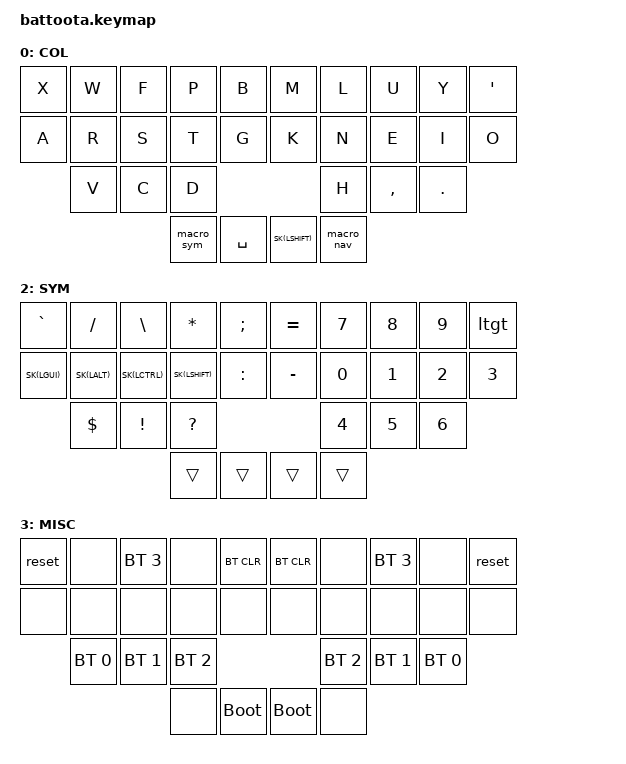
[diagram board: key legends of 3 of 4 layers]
/*
 * Copyright (c) 2020 The ZMK Contributors
 *
 * SPDX-License-Identifier: MIT
 */

#include <behaviors.dtsi>
#include <dt-bindings/zmk/keys.h>
#include <dt-bindings/zmk/bt.h>
#include <dt-bindings/zmk/outputs.h>

#define COL 0
#define NAV 1
#define SYM 2
#define MISC 4

#define SK(KEY) &nk KEY KEY
// Keep sticky keys active for a long time so they effectively do not time out
#define STICKY_KEY_TIMEOUT 60000

&sk {
  release-after-ms = <STICKY_KEY_TIMEOUT>;
};

&caps_word {
  continue-list = <UNDERSCORE MINUS BACKSPACE>;
};

/ { 

     ZMK_MACRO(macro_nav,
        wait-ms = <0>;
        tap-ms = <0>;
        bindings
        = <&macro_tap &kp K_CANCEL>
        , <&macro_press &mo NAV>
        , <&macro_pause_for_release>
        , <&macro_release &mo NAV>;)

     ZMK_MACRO(macro_sym,
        wait-ms = <0>;
        tap-ms = <0>;
        bindings
        = <&macro_tap &kp K_CANCEL>
        , <&macro_press &mo SYM>
        , <&macro_pause_for_release>
        , <&macro_release &mo SYM>;)

     ZMK_MACRO(macro_power,
        wait-ms = <30>;
        tap-ms = <40>;
        bindings
        = <&macro_tap_time 1000> 
        , <&kp C_POWER>;)

     ZMK_MACRO(macro_sleep,
        wait-ms = <30>;
        tap-ms = <40>;
        bindings
        = <&macro_tap_time 1000> 
        , <&kp C_SLEEP>;)

    combos {
        compatible = "zmk,combos"; 
        #define COMBO(NAME, BINDINGS, KEYPOS, LAYERS) \
        combo_##NAME { \
            bindings = <BINDINGS>; \
            timeout-ms = <40>; \
            key-positions = <KEYPOS>; \
            layers = <LAYERS>; \
        };

        /* Missing Alphas */
        COMBO(Z, &kp Z, 21 22, COL) // Z 
        COMBO(Q, &kp Q, 20 21, COL) // Q
        COMBO(Q2, &kp Q, 2 3, COL) // Q for vim wq
        COMBO(J, &kp J, 1 2, COL) // J 
        COMBO(slash, &kp SLASH, 24 25, COL) // slash
        COMBO(dot, &kp DOT, 16 17, SYM) // .
        COMBO(comma, &kp COMMA, 17 18, SYM) // ,

        /* Brackets */
        COMBO(left_bracket, &kp LBKT, 1 11, COL)
        COMBO(right_bracket, &kp RBKT, 8 18, COL)
        COMBO(left_parenthesis, &kp LPAR, 2 12, COL)
        COMBO(right_parenthesis, &kp RPAR, 7 17, COL)
        COMBO(left_brace, &kp LBRC, 3 13, COL)
        COMBO(right_brace, &kp RBRC, 6 16, COL)

        /* Text processing */
        COMBO(undo, &kp LG(Z), 10 20, COL)
        COMBO(redo, &kp LG(LS(Z)), 10 21, COL)
        COMBO(select_all, &kp LG(A), 10 22, COL)
        COMBO(cut, &kp LG(X), 11 20 , COL)
        COMBO(copy, &kp LG(C), 12 21, COL)
        COMBO(paste, &kp LG(V), 20 21 22, COL)
        COMBO(caps_word, &caps_word, 27 28, COL)

        /* one hand */
        COMBO(nav1h, &macro_nav, 26 27, COL)
        COMBO(sym1h, &macro_sym, 28 29, COL)

        /* misc */
        COMBO(alfred, &kp LG(SPACE), 22 23, COL)
        COMBO(clpbrd, &kp LG(LC(LA(LS(Z)))), 14 15, COL)
        COMBO(esc, &kp ESC, 22 26, COL)
        COMBO(enter, &kp ENTER, 13 22, COL)
        COMBO(backspace, &kp BACKSPACE, 4 14, COL)
        COMBO(key_repeat, &key_repeat, 16 23, COL)
        COMBO(delete_word, &kp LA(BACKSPACE), 5 15, COL)

        #define GCOMBO(NAME, BINDINGS, KEYPOS) \
        combo_##NAME { \
            bindings = <BINDINGS>; \
            key-positions = <KEYPOS>; \
        };
        /* layers */
        GCOMBO(switch_to_mac, &to COL, 12 13 26)
        GCOMBO(misc_layertL, &to MISC, 11 12 13 14)
        GCOMBO(misc_layerR, &to MISC, 15 16 17 18)

    };
  
    // Sticky key on tap, normal key on hold
    // Useful for modifier-clicking without the modifier remaining active
     nk: not_so_sticky_key {
       compatible = "zmk,behavior-hold-tap";
       label = "NOT_SO_STICKY_KEY";
       #binding-cells = <2>;
       tapping_term_ms = <200>;
       flavor = "tap-preferred";
       bindings = <&kp>, <&sk>;
     };

     ltgt: smaller_bigger {
            compatible = "zmk,behavior-mod-morph";
            label = "SMALLER_BIGGER";
            #binding-cells = <0>;
            bindings = <&kp LT>, <&kp GT>;
            mods = <(MOD_LSFT)>;
        };
 
        keymap {
                compatible = "zmk,keymap";

        colemak {
            label = "COL";
            bindings = <
// ╭─────────────┬─────────────┬─────────────┬─────────────┬─────────────╮   ╭─────────────┬─────────────┬─────────────┬─────────────┬─────────────╮
     &kp X         &kp W         &kp F         &kp P         &kp B             &kp M         &kp L         &kp U         &kp Y         &kp SQT
// ├─────────────┼─────────────┼─────────────┼─────────────┼─────────────┤   ├─────────────┼─────────────┼─────────────┼─────────────┼─────────────┤
     &kp A         &kp R         &kp S         &kp T         &kp G             &kp K         &kp N         &kp E         &kp I         &kp O
// ├─────────────┼─────────────┼─────────────┼─────────────┼─────────────┤   ├─────────────┼─────────────┼─────────────┼─────────────┼─────────────┤
                   &kp V         &kp C         &kp D                                         &kp H         &kp COMMA     &kp DOT
//               ╰─────────────┴─────────────┼─────────────┤                               ├─────────────┼─────────────┴─────────────╯
                                               &macro_sym    &kp SPACE         SK(LSHIFT)    &macro_nav
//                                           ╰─────────────┴─────────────╯   ╰─────────────┴─────────────╯
            >;
        };

        navitation {
            label = "NAV";
            bindings = <
// ╭─────────────┬─────────────┬─────────────┬─────────────┬─────────────╮   ╭─────────────┬─────────────┬─────────────┬─────────────┬─────────────╮
     &kp LG(Q)     &kp DELETE    &kp UP        &kp LG(F)     &kp BACKSPACE     &kp LG(LS(T)) &kp LG(W)     &kp LG(R)     &kp LG(T)     &kp LG(LC(LA(LS(P))))
// ├─────────────┼─────────────┼─────────────┼─────────────┼─────────────┤   ├─────────────┼─────────────┼─────────────┼─────────────┼─────────────┤
     &kp TAB       &kp LEFT      &kp DOWN       &kp RIGHT    &kp ENTER         &kp LG(A)     SK(LSHIFT)    SK(LCTRL)     SK(LALT)      SK(LGUI)
// ├─────────────┼─────────────┼─────────────┼─────────────┼─────────────┤   ├─────────────┼─────────────┼─────────────┼─────────────┼─────────────┤
                &kp LA(LC(LEFT)) &kp LA(LC(ENTER)) &kp LA(LC(RIGHT))                         &kp C_SLEEP   &macro_power  &kp LG(LC(Q))
//               ╰─────────────┴─────────────┼─────────────┤                               ├─────────────┼─────────────┴─────────────╯
                                              &trans          &trans             &trans        &trans
//                                           ╰─────────────┴─────────────╯   ╰─────────────┴─────────────╯
            >;
        };
        symbols {
            label = "SYM";
            bindings = <
// ╭─────────────┬─────────────┬─────────────┬─────────────┬─────────────╮   ╭─────────────┬─────────────┬─────────────┬─────────────┬─────────────╮
     &kp GRAVE      &kp SLASH    &kp BSLH     &kp ASTRK      &kp SEMI           &kp EQUAL     &kp N7       &kp N8         &kp N9       &ltgt
// ├─────────────┼─────────────┼─────────────┼─────────────┼─────────────┤   ├─────────────┼─────────────┼─────────────┼─────────────┼─────────────┤
     SK(LGUI)      SK(LALT)      SK(LCTRL)     SK(LSHIFT)    &kp COLON          &kp MINUS     &kp N0       &kp N1       &kp N2         &kp N3
// ├─────────────┼─────────────┼─────────────┼─────────────┼─────────────┤   ├─────────────┼─────────────┼─────────────┼─────────────┼─────────────┤
                   &kp DLLR      &kp EXCL      &kp QMARK                                      &kp N4       &kp N5         &kp N6
//               ╰─────────────┴─────────────┼─────────────┤                               ├─────────────┼─────────────┴─────────────╯
                                               &trans          &trans           &trans       &trans
//                                           ╰─────────────┴─────────────╯   ╰─────────────┴─────────────╯
            >;
        };

        miscellaneous {
            label = "MISC";
            bindings = <
// ╭─────────────┬─────────────┬─────────────┬─────────────┬─────────────╮   ╭─────────────┬─────────────┬─────────────┬─────────────┬─────────────╮
     &reset        &none         &bt BT_SEL 3  &none         &bt BT_CLR        &bt BT_CLR    &none         &bt BT_SEL 3  &none         &reset
// ├─────────────┼─────────────┼─────────────┼─────────────┼─────────────┤   ├─────────────┼─────────────┼─────────────┼─────────────┼─────────────┤
     &none         &none         &none         &none         &none             &none         &none        &none          &none          &none
// ├─────────────┼─────────────┼─────────────┼─────────────┼─────────────┤   ├─────────────┼─────────────┼─────────────┼─────────────┼─────────────┤
                   &bt BT_SEL 0   &bt BT_SEL 1  &bt BT_SEL 2                                 &bt BT_SEL 2   &bt BT_SEL 1  &bt BT_SEL 0
//               ╰─────────────┴─────────────┼─────────────┤                               ├─────────────┼─────────────┴─────────────╯
                                               &none         &bootloader       &bootloader   &none
//                                           ╰─────────────┴─────────────╯   ╰─────────────┴─────────────╯
            >;
        };
};

};
